# ATtiny1604 register map
Vendor: Atmel; File version: 1.0
CPU: other r0p0, little endian, no MPU, no FPU, 4 interrupt priority bits
Registers are 8-bit, read-write, reset 0x0 unless marked. A register's access mark holds for its fields unless they carry their own. Offsets are from the block's base; [hi:lo] are bit positions; {n}, {i} and the like mark numbered series; 'fields as' and 'values as' point back to an identical list.

## CPU
Base 0x00800034
0x00 CCP — Configuration Change Protection
  [7:0] CCP — CCP signature
    157=SPM (SPM Instruction Protection); 216=IOREG (IO Register Protection)
0x09 SPL — Stack Pointer Low
0x0A SPH — Stack Pointer High

## CPUINT — Interrupt Controller
Base 0x00800110
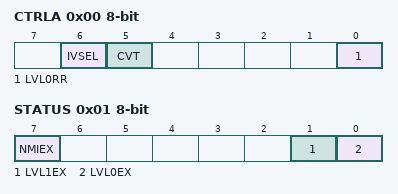
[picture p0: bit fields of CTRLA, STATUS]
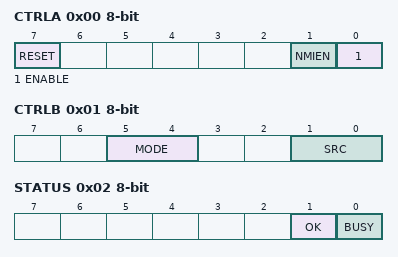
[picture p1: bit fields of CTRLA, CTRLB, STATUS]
0x00 CTRLA — Control A
  [6] IVSEL — Interrupt Vector Select
  [5] CVT — Compact Vector Table
  [0] LVL0RR — Round-robin Scheduling Enable
0x01 STATUS
  [7] NMIEX ro — Non-maskable Interrupt Executing
  [1] LVL1EX ro — Level 1 Interrupt Executing
  [0] LVL0EX ro — Level 0 Interrupt Executing
0x02 LVL0PRI — Interrupt Level 0 Priority
  [7:0] LVL0PRI — Interrupt Level Priority
0x03 LVL1VEC — Interrupt Level 1 Priority Vector
  [7:0] LVL1VEC — Interrupt Vector with High Priority

## CRCSCAN
Base 0x00800120
0x00 CTRLA — Control A
  [7] RESET — Reset CRC scan
  [1] NMIEN — Enable NMI Trigger
  [0] ENABLE — Enable CRC scan
0x01 CTRLB — Control B
  [5:4] MODE — CRC Flash Access Mode
    0=PRIORITY (Priority to flash)
  [1:0] SRC — CRC Source
    0=FLASH (CRC on entire flash); 1=APPLICATION (CRC on boot and appl section of flash); 2=BOOT (CRC on boot section of flash)
0x02 STATUS ro
  [1] OK — CRC Ok
  [0] BUSY — CRC Busy

## FUSE — Fuses
Base 0x00801280
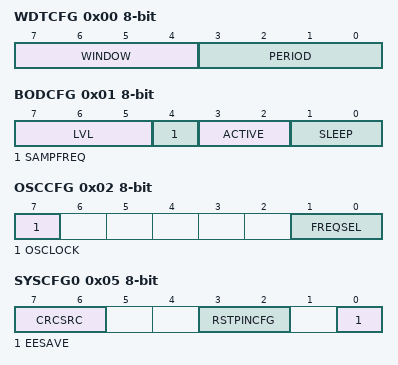
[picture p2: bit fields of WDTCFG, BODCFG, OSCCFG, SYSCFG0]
0x00 WDTCFG — Watchdog Configuration
  [7:4] WINDOW — Watchdog Window Timeout Period
    0=OFF; 1=8CLK (8 cycles (8ms)); 2=16CLK (16 cycles (16ms)); 3=32CLK (32 cycles (32ms)); 4=64CLK (64 cycles (64ms)); 5=128CLK (128 cycles (0.128s)); 6=256CLK (256 cycles (0.256s)); 7=512CLK (512 cycles (0.512s)); 8=1KCLK (1K cycles (1.0s)); 9=2KCLK (2K cycles (2.0s)); 10=4KCLK (4K cycles (4.1s)); 11=8KCLK (8K cycles (8.2s))
  [3:0] PERIOD — Watchdog Timeout Period
    values as WINDOW
0x01 BODCFG — BOD Configuration
  [7:5] LVL — BOD Level
    0=BODLEVEL0 (1.8 V); 2=BODLEVEL2 (2.6 V); 7=BODLEVEL7 (4.2 V)
  [4] SAMPFREQ — BOD Sample Frequency
    0=1KHZ (1kHz sampling frequency); 1=125HZ (125Hz sampling frequency)
  [3:2] ACTIVE — BOD Operation in Active Mode
    0=DIS (Disabled); 1=ENABLED; 2=SAMPLED; 3=ENWAKE (Enabled with wake-up halted until BOD is ready)
  [1:0] SLEEP — BOD Operation in Sleep Mode
    0=DIS (Disabled); 1=ENABLED; 2=SAMPLED
0x02 OSCCFG — Oscillator Configuration
  [7] OSCLOCK — Oscillator Lock
  [1:0] FREQSEL — Frequency Select
    1=16MHZ; 2=20MHZ
0x05 SYSCFG0 — System Configuration 0
  [7:6] CRCSRC — CRC Source
    0=FLASH (The CRC is performed on the entire Flash (boot, application code and application data section).); 1=BOOT (The CRC is performed on the boot section of Flash); 2=BOOTAPP (The CRC is performed on the boot and application code section of Flash); 3=NOCRC (Disable CRC.)
  [3:2] RSTPINCFG — Reset Pin Configuration
    0=GPIO (GPIO mode); 1=UPDI (UPDI mode); 2=RST (Reset mode)
  [0] EESAVE — EEPROM Save
0x06 SYSCFG1 — System Configuration 1
  [2:0] SUT — Startup Time
    0=0MS; 1=1MS; 2=2MS; 3=4MS; 4=8MS; 5=16MS; 6=32MS; 7=64MS
0x07 APPEND — Application Code Section End
0x08 BOOTEND — Boot Section End

## GPIO — General Purpose IO
Base 0x0080001C
{0x0+i} GPIOR{i} (i=0..3) — General Purpose IO Register {i}

## LOCKBIT
Base 0x0080128A
0x00 LOCKBIT — Lock bits
  [7:0] LB — Lock Bits
    58=RWLOCK (Read and write lock); 197=NOLOCK (No locks)

## NVMCTRL — Non-volatile Memory Controller
Base 0x00801000
0x00 CTRLA — Control A
  [2:0] CMD — Command
    0=NONE (No Command); 1=PAGEWRITE (Write page); 2=PAGEERASE (Erase page); 3=PAGEERASEWRITE (Erase and write page); 4=PAGEBUFCLR (Page buffer clear); 5=CHIPERASE; 6=EEERASE (EEPROM erase); 7=FUSEWRITE (Write fuse (PDI only))
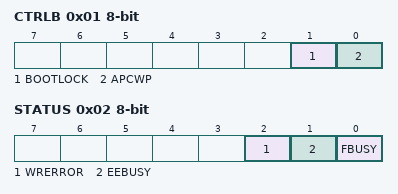
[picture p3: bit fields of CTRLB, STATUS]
0x01 CTRLB — Control B
  [1] BOOTLOCK
  [0] APCWP — Application code write protect
0x02 STATUS ro
  [2] WRERROR — Write error
  [1] EEBUSY — EEPROM busy
  [0] FBUSY — Flash busy
0x03 INTCTRL — Interrupt Control
  [0] EEREADY — EEPROM Ready
0x04 INTFLAGS — Interrupt Flags
  [0] EEREADY — EEPROM Ready
0x06 DATA 16-bit (reset mask 0xFF)
0x08 ADDR 16-bit (reset mask 0xFF) — Address
